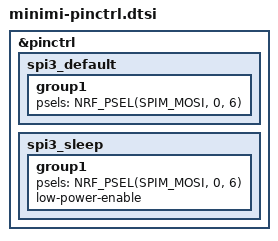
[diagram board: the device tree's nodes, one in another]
// This file was generated from a template. Edit it to match your keyboard.
// See https://docs.zephyrproject.org/4.1.0/hardware/porting/board_porting.html
// and https://docs.zephyrproject.org/4.1.0/hardware/pinctrl/index.html for
// more instructions.

#include <dt-bindings/pinctrl/nrf-pinctrl.h>

&pinctrl {
    spi3_default: spi3_default {
        group1 {
            psels = <NRF_PSEL(SPIM_MOSI, 0, 6)>;
        };
    };

    spi3_sleep: spi3_sleep {
        group1 {
            psels = <NRF_PSEL(SPIM_MOSI, 0, 6)>;
            low-power-enable;
        };
    };
};
